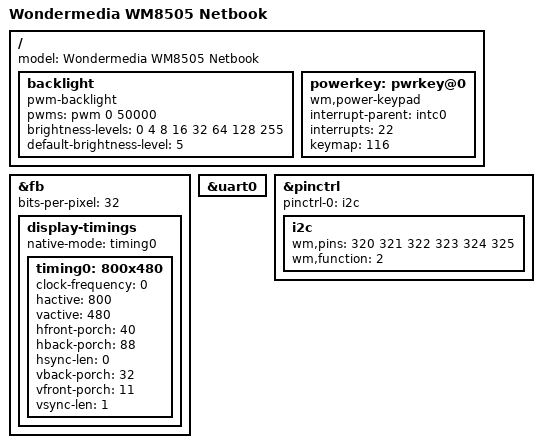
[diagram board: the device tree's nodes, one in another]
/*
 * wm8505-ref.dts - Device tree file for Wondermedia WM8505 reference netbook
 *
 * Copyright (C) 2012 Tony Prisk <linux@prisktech.co.nz>
 *
 * Licensed under GPLv2 or later
 */

/dts-v1/;
/include/ "wm8505.dtsi"

/ {
	model = "Wondermedia WM8505 Netbook";

	backlight {
		compatible = "pwm-backlight";
		pwms = <&pwm 0 50000>;

		brightness-levels = <0 4 8 16 32 64 128 255>;
		default-brightness-level = <5>;
	};

	powerkey: pwrkey@0 {
		compatible = "wm,power-keypad";
		interrupt-parent = <&intc0>;
		interrupts = <22>;
		keymap = <116>; /* KEY_POWER */
	};
};

&fb {
	bits-per-pixel = <32>;
	display-timings {
		native-mode = <&timing0>;
		timing0: 800x480 {
			clock-frequency = <0>; /* unused but required */
			hactive = <800>;
			vactive = <480>;
			hfront-porch = <40>;
			hback-porch = <88>;
			hsync-len = <0>;
			vback-porch = <32>;
			vfront-porch = <11>;
			vsync-len = <1>;
		};
	};
};

&uart0 {
	status = "okay";
};

&pinctrl {
	pinctrl-names = "default";
	pinctrl-0 = <&i2c>;

	i2c: i2c {
		wm,pins = <320 321 322 323 324 325>;
		wm,function = <2>;
	};
};

&uart0 {
	status = "okay";
};
